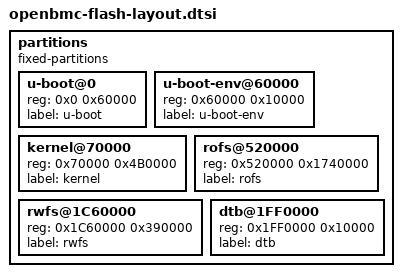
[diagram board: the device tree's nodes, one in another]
// SPDX-License-Identifier: GPL-2.0+

partitions {
	compatible = "fixed-partitions";
	#address-cells = <1>;
	#size-cells = <1>;

	u-boot@0 {
		reg = <0x0 0x60000>;
		label = "u-boot";
	};

	u-boot-env@60000 {
		reg = <0x60000 0x10000>;
		label = "u-boot-env";
	};

	kernel@70000 {
		reg = <0x70000 0x4B0000>;
		label = "kernel";
	};

	rofs@520000 {
		reg = <0x520000 0x1740000>;
		label = "rofs";
	};

	rwfs@1C60000 {
		reg = <0x1C60000 0x390000>;
		label = "rwfs";
	};
	
	dtb@1FF0000 {
		reg = <0x1FF0000 0x10000>;
		label = "dtb";
	};	
};
